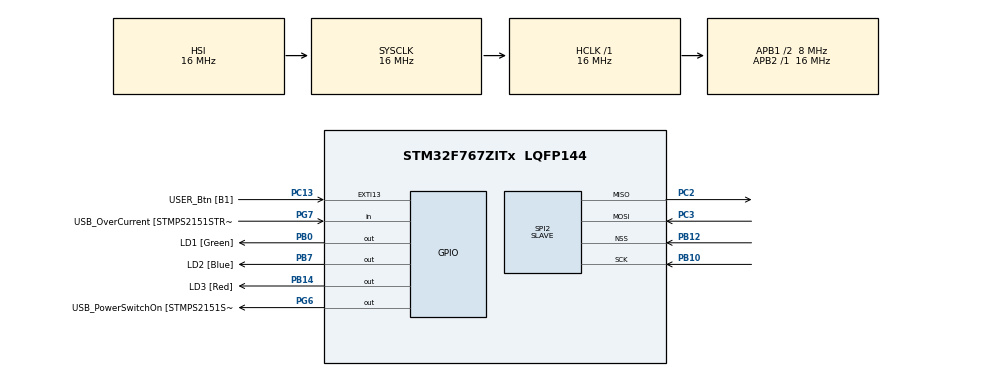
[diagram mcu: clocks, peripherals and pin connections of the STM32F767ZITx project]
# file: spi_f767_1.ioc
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Dma.Request0=SPI2_RX
Dma.Request1=SPI2_TX
Dma.SPI2_RX.0.Direction=DMA_PERIPH_TO_MEMORY
Dma.SPI2_RX.0.FIFOMode=DMA_FIFOMODE_DISABLE
Dma.SPI2_RX.0.Instance=DMA1_Stream1
Dma.SPI2_RX.0.MemDataAlignment=DMA_MDATAALIGN_BYTE
Dma.SPI2_RX.0.MemInc=DMA_MINC_ENABLE
Dma.SPI2_RX.0.Mode=DMA_NORMAL
Dma.SPI2_RX.0.PeriphDataAlignment=DMA_PDATAALIGN_BYTE
Dma.SPI2_RX.0.PeriphInc=DMA_PINC_DISABLE
Dma.SPI2_RX.0.Priority=DMA_PRIORITY_LOW
Dma.SPI2_TX.1.Direction=DMA_MEMORY_TO_PERIPH
Dma.SPI2_TX.1.FIFOMode=DMA_FIFOMODE_DISABLE
Dma.SPI2_TX.1.Instance=DMA1_Stream4
Dma.SPI2_TX.1.MemDataAlignment=DMA_MDATAALIGN_BYTE
Dma.SPI2_TX.1.MemInc=DMA_MINC_ENABLE
Dma.SPI2_TX.1.Mode=DMA_NORMAL
Dma.SPI2_TX.1.PeriphDataAlignment=DMA_PDATAALIGN_BYTE
Dma.SPI2_TX.1.PeriphInc=DMA_PINC_DISABLE
Dma.SPI2_TX.1.Priority=DMA_PRIORITY_LOW
FREERTOS.BinarySemaphores01=spi_data,Dynamic,NULL
FREERTOS.Tasks01=defaultTask,24,128,StartDefaultTask,Default,NULL,Dynamic,NULL,NULL;spi_handler,25,128,spi_handler_entry,Default,NULL,Dynamic,NULL,NULL
FREERTOS.configUSE_NEWLIB_REENTRANT=1
Mcu.Family=STM32F7
Mcu.Name=STM32F767ZITx
Mcu.Package=LQFP144
NVIC.DMA1_Stream1_IRQn=true\:5\:0\:false\:false\:true\:true\:false\:true\:true
NVIC.DMA1_Stream4_IRQn=true\:5\:0\:false\:false\:true\:true\:false\:true\:true
NVIC.PriorityGroup=NVIC_PRIORITYGROUP_4
NVIC.SPI2_IRQn=true\:5\:0\:false\:false\:true\:true\:true\:true\:true
PA1.GPIO_Label=RMII_REF_CLK [LAN8742A-CZ-TR_REFCLK0]
PA1.Signal=ETH_REF_CLK
PA10.GPIO_Label=USB_ID
PA10.Signal=USB_OTG_FS_ID
PA11.GPIO_Label=USB_DM
PA11.Signal=USB_OTG_FS_DM
PA12.GPIO_Label=USB_DP
PA12.Signal=USB_OTG_FS_DP
PA13.GPIO_Label=TMS
PA13.Signal=SYS_JTMS-SWDIO
PA14.GPIO_Label=TCK
PA14.Signal=SYS_JTCK-SWCLK
PA2.GPIO_Label=RMII_MDIO [LAN8742A-CZ-TR_MDIO]
PA2.Signal=ETH_MDIO
PA7.GPIO_Label=RMII_CRS_DV [LAN8742A-CZ-TR_CRS_DV]
PA7.Signal=ETH_CRS_DV
PA8.GPIO_Label=USB_SOF [TP1]
PA8.Signal=USB_OTG_FS_SOF
PA9.GPIO_Label=USB_VBUS
PA9.Signal=USB_OTG_FS_VBUS
PB0.GPIO_Label=LD1 [Green]
PB0.Signal=GPIO_Output
PB10.Mode=Full_Duplex_Slave
PB10.Signal=SPI2_SCK
PB12.Mode=NSS_Signal_Hard_Input
PB12.Signal=SPI2_NSS
PB13.GPIO_Label=RMII_TXD1 [LAN8742A-CZ-TR_TXD1]
PB13.Signal=ETH_TXD1
PB14.GPIO_Label=LD3 [Red]
PB14.Signal=GPIO_Output
PB3.GPIO_Label=SW0
PB3.Signal=SYS_JTDO-SWO
PB7.GPIO_Label=LD2 [Blue]
PB7.Signal=GPIO_Output
PC1.GPIO_Label=RMII_MDC [LAN8742A-CZ-TR_MDC]
PC1.Signal=ETH_MDC
PC13.GPIO_Label=USER_Btn [B1]
PC13.Signal=GPXTI13
PC14/OSC32_IN.Signal=RCC_OSC32_IN
PC15/OSC32_OUT.Signal=RCC_OSC32_OUT
PC2.Mode=Full_Duplex_Slave
PC2.Signal=SPI2_MISO
PC3.Mode=Full_Duplex_Slave
PC3.Signal=SPI2_MOSI
PC4.GPIO_Label=RMII_RXD0 [LAN8742A-CZ-TR_RXD0]
PC4.Signal=ETH_RXD0
PC5.GPIO_Label=RMII_RXD1 [LAN8742A-CZ-TR_RXD1]
PC5.Signal=ETH_RXD1
PD8.GPIO_Label=STLK_RX [STM32F103CBT6_PA3]
PD8.Signal=USART3_TX
PD9.GPIO_Label=STLK_TX [STM32F103CBT6_PA2]
PD9.Signal=USART3_RX
PG11.GPIO_Label=RMII_TX_EN [LAN8742A-CZ-TR_TXEN]
PG11.Signal=ETH_TX_EN
PG13.GPIO_Label=RMII_TXD0 [LAN8742A-CZ-TR_TXD0]
PG13.Signal=ETH_TXD0
PG6.GPIO_Label=USB_PowerSwitchOn [STMPS2151STR_EN]
PG6.Signal=GPIO_Output
PG7.GPIO_Label=USB_OverCurrent [STMPS2151STR_FAULT]
PG7.Signal=GPIO_Input
PH0/OSC_IN.GPIO_Label=MCO [STM32F103CBT6_PA8]
PH0/OSC_IN.Signal=RCC_OSC_IN
PH1/OSC_OUT.Signal=RCC_OSC_OUT
ProjectManager.HeapSize=0x200
ProjectManager.StackSize=0x400
ProjectManager.TargetToolchain=STM32CubeIDE
RCC.48MHZClocksFreq_Value=24000000
RCC.AHBFreq_Value=16000000
RCC.APB1CLKDivider=RCC_HCLK_DIV2
RCC.APB1Freq_Value=8000000
RCC.APB1TimFreq_Value=16000000
RCC.APB2Freq_Value=16000000
RCC.APB2TimFreq_Value=16000000
RCC.CortexFreq_Value=16000000
RCC.HCLKFreq_Value=16000000
RCC.HSE_VALUE=16000000
RCC.HSI_VALUE=16000000
RCC.LSE_VALUE=32768
RCC.PLLMUL=RCC_PLL_MUL9
RCC.PRESCALERUSB=RCC_USBCLKSOURCE_PLL_DIV1_5
RCC.SYSCLKFreq_VALUE=16000000
RCC.SYSCLKSourceVirtual=RCC_SYSCLKSOURCE_PLLCLK
RCC.USBFreq_Value=96000000
RCC.VCOOutputFreq_Value=192000000
SPI2.DataSize=SPI_DATASIZE_8BIT
SPI2.Direction=SPI_DIRECTION_2LINES
SPI2.Mode=SPI_MODE_SLAVE
SPI2.VirtualNSS=VM_NSSHARD
SPI2.VirtualType=VM_SLAVE
VP_FREERTOS_VS_CMSIS_V2.Mode=CMSIS_V2
board=NUCLEO-F767ZI

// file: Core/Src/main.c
/* USER CODE BEGIN Header */
/**
  ******************************************************************************
  * @file           : main.c
  * @brief          : Main program body
  ******************************************************************************
  * @attention
  *
  * Copyright (c) 2024 STMicroelectronics.
  * All rights reserved.
  *
  * This software is licensed under terms that can be found in the LICENSE file
  * in the root directory of this software component.
  * If no LICENSE file comes with this software, it is provided AS-IS.
  *
  ******************************************************************************
  */
/* USER CODE END Header */
#include "main.h"
#include "cmsis_os.h"

SPI_HandleTypeDef hspi2;
DMA_HandleTypeDef hdma_spi2_rx;
DMA_HandleTypeDef hdma_spi2_tx;

/* Definitions for defaultTask */
osThreadId_t defaultTaskHandle;
const osThreadAttr_t defaultTask_attributes = {
  .name = "defaultTask",
  .stack_size = 128 * 4,
  .priority = (osPriority_t) osPriorityNormal,
};
/* Definitions for spi_handler */
osThreadId_t spi_handlerHandle;
const osThreadAttr_t spi_handler_attributes = {
  .name = "spi_handler",
  .stack_size = 128 * 4,
  .priority = (osPriority_t) osPriorityNormal1,
};
/* Definitions for spi_data */
osSemaphoreId_t spi_dataHandle;
const osSemaphoreAttr_t spi_data_attributes = {
  .name = "spi_data"
};

void SystemClock_Config(void);
static void MX_GPIO_Init(void);
static void MX_DMA_Init(void);
static void MX_SPI2_Init(void);
void StartDefaultTask(void *argument);
void spi_handler_entry(void *argument);

/* USER CODE BEGIN 0 */
#define TRANSFER_SIZE 64

uint8_t transfer_bytes[TRANSFER_SIZE] = {0};

void HAL_SPI_RxCpltCallback(SPI_HandleTypeDef *hspi)
{
	//HAL_SPI_Receive_IT(&hspi2, transfer_bytes, TRANSFER_SIZE);
	HAL_GPIO_TogglePin(GPIOB, GPIO_PIN_14);
	osSemaphoreRelease(spi_dataHandle);

}
void HAL_SPI_TxCpltCallback(SPI_HandleTypeDef *hspi)
{
	HAL_SPI_Receive_DMA(&hspi2, transfer_bytes, TRANSFER_SIZE);

}
/* USER CODE END 0 */

int main(void)
{

  /* MCU Configuration--------------------------------------------------------*/

  /* Reset of all peripherals, Initializes the Flash interface and the Systick. */
  HAL_Init();

  /* Configure the system clock */
  SystemClock_Config();

  /* Initialize all configured peripherals */
  MX_GPIO_Init();
  MX_DMA_Init();
  MX_SPI2_Init();
  /* USER CODE BEGIN 2 */
  HAL_SPI_Receive_DMA(&hspi2, transfer_bytes, TRANSFER_SIZE);

  /* USER CODE END 2 */

  /* Init scheduler */
  osKernelInitialize();

  /* Create the semaphores(s) */
  /* creation of spi_data */
  spi_dataHandle = osSemaphoreNew(1, 0, &spi_data_attributes);

  /* Create the thread(s) */
  /* creation of defaultTask */
  defaultTaskHandle = osThreadNew(StartDefaultTask, NULL, &defaultTask_attributes);

  /* creation of spi_handler */
  spi_handlerHandle = osThreadNew(spi_handler_entry, NULL, &spi_handler_attributes);

  /* Start scheduler */
  osKernelStart();

  /* We should never get here as control is now taken by the scheduler */

  /* Infinite loop */
  while (1)
  {

  }
}

void SystemClock_Config(void)
{
  RCC_OscInitTypeDef RCC_OscInitStruct = {0};
  RCC_ClkInitTypeDef RCC_ClkInitStruct = {0};

  /** Configure the main internal regulator output voltage
  */
  __HAL_RCC_PWR_CLK_ENABLE();
  __HAL_PWR_VOLTAGESCALING_CONFIG(PWR_REGULATOR_VOLTAGE_SCALE3);

  /** Initializes the RCC Oscillators according to the specified parameters
  * in the RCC_OscInitTypeDef structure.
  */
  RCC_OscInitStruct.OscillatorType = RCC_OSCILLATORTYPE_HSI;
  RCC_OscInitStruct.HSIState = RCC_HSI_ON;
  RCC_OscInitStruct.HSICalibrationValue = RCC_HSICALIBRATION_DEFAULT;
  RCC_OscInitStruct.PLL.PLLState = RCC_PLL_NONE;
  if (HAL_RCC_OscConfig(&RCC_OscInitStruct) != HAL_OK)
  {
    Error_Handler();
  }

  /** Initializes the CPU, AHB and APB buses clocks
  */
  RCC_ClkInitStruct.ClockType = RCC_CLOCKTYPE_HCLK|RCC_CLOCKTYPE_SYSCLK
                              |RCC_CLOCKTYPE_PCLK1|RCC_CLOCKTYPE_PCLK2;
  RCC_ClkInitStruct.SYSCLKSource = RCC_SYSCLKSOURCE_HSI;
  RCC_ClkInitStruct.AHBCLKDivider = RCC_SYSCLK_DIV1;
  RCC_ClkInitStruct.APB1CLKDivider = RCC_HCLK_DIV2;
  RCC_ClkInitStruct.APB2CLKDivider = RCC_HCLK_DIV1;

  if (HAL_RCC_ClockConfig(&RCC_ClkInitStruct, FLASH_LATENCY_0) != HAL_OK)
  {
    Error_Handler();
  }
}

static void MX_SPI2_Init(void)
{

  /* SPI2 parameter configuration*/
  hspi2.Instance = SPI2;
  hspi2.Init.Mode = SPI_MODE_SLAVE;
  hspi2.Init.Direction = SPI_DIRECTION_2LINES;
  hspi2.Init.DataSize = SPI_DATASIZE_8BIT;
  hspi2.Init.CLKPolarity = SPI_POLARITY_LOW;
  hspi2.Init.CLKPhase = SPI_PHASE_1EDGE;
  hspi2.Init.NSS = SPI_NSS_HARD_INPUT;
  hspi2.Init.FirstBit = SPI_FIRSTBIT_MSB;
  hspi2.Init.TIMode = SPI_TIMODE_DISABLE;
  hspi2.Init.CRCCalculation = SPI_CRCCALCULATION_DISABLE;
  hspi2.Init.CRCPolynomial = 7;
  hspi2.Init.CRCLength = SPI_CRC_LENGTH_DATASIZE;
  hspi2.Init.NSSPMode = SPI_NSS_PULSE_DISABLE;
  if (HAL_SPI_Init(&hspi2) != HAL_OK)
  {
    Error_Handler();
  }

}

static void MX_DMA_Init(void)
{

  /* DMA controller clock enable */
  __HAL_RCC_DMA1_CLK_ENABLE();

  /* DMA interrupt init */
  /* DMA1_Stream1_IRQn interrupt configuration */
  HAL_NVIC_SetPriority(DMA1_Stream1_IRQn, 5, 0);
  HAL_NVIC_EnableIRQ(DMA1_Stream1_IRQn);
  /* DMA1_Stream4_IRQn interrupt configuration */
  HAL_NVIC_SetPriority(DMA1_Stream4_IRQn, 5, 0);
  HAL_NVIC_EnableIRQ(DMA1_Stream4_IRQn);

}

static void MX_GPIO_Init(void)
{
  GPIO_InitTypeDef GPIO_InitStruct = {0};

  /* GPIO Ports Clock Enable */
  __HAL_RCC_GPIOC_CLK_ENABLE();
  __HAL_RCC_GPIOH_CLK_ENABLE();
  __HAL_RCC_GPIOA_CLK_ENABLE();
  __HAL_RCC_GPIOB_CLK_ENABLE();
  __HAL_RCC_GPIOD_CLK_ENABLE();
  __HAL_RCC_GPIOG_CLK_ENABLE();

  /*Configure GPIO pin Output Level */
  HAL_GPIO_WritePin(GPIOB, LD1_Pin|LD3_Pin|LD2_Pin, GPIO_PIN_RESET);

  /*Configure GPIO pin Output Level */
  HAL_GPIO_WritePin(USB_PowerSwitchOn_GPIO_Port, USB_PowerSwitchOn_Pin, GPIO_PIN_RESET);

  /*Configure GPIO pin : USER_Btn_Pin */
  GPIO_InitStruct.Pin = USER_Btn_Pin;
  GPIO_InitStruct.Mode = GPIO_MODE_IT_RISING;
  GPIO_InitStruct.Pull = GPIO_NOPULL;
  HAL_GPIO_Init(USER_Btn_GPIO_Port, &GPIO_InitStruct);

  /*Configure GPIO pins : RMII_MDC_Pin RMII_RXD0_Pin RMII_RXD1_Pin */
  GPIO_InitStruct.Pin = RMII_MDC_Pin|RMII_RXD0_Pin|RMII_RXD1_Pin;
  GPIO_InitStruct.Mode = GPIO_MODE_AF_PP;
  GPIO_InitStruct.Pull = GPIO_NOPULL;
  GPIO_InitStruct.Speed = GPIO_SPEED_FREQ_VERY_HIGH;
  GPIO_InitStruct.Alternate = GPIO_AF11_ETH;
  HAL_GPIO_Init(GPIOC, &GPIO_InitStruct);

  /*Configure GPIO pins : RMII_REF_CLK_Pin RMII_MDIO_Pin RMII_CRS_DV_Pin */
  GPIO_InitStruct.Pin = RMII_REF_CLK_Pin|RMII_MDIO_Pin|RMII_CRS_DV_Pin;
  GPIO_InitStruct.Mode = GPIO_MODE_AF_PP;
  GPIO_InitStruct.Pull = GPIO_NOPULL;
  GPIO_InitStruct.Speed = GPIO_SPEED_FREQ_VERY_HIGH;
  GPIO_InitStruct.Alternate = GPIO_AF11_ETH;
  HAL_GPIO_Init(GPIOA, &GPIO_InitStruct);

  /*Configure GPIO pins : LD1_Pin LD3_Pin LD2_Pin */
  GPIO_InitStruct.Pin = LD1_Pin|LD3_Pin|LD2_Pin;
  GPIO_InitStruct.Mode = GPIO_MODE_OUTPUT_PP;
  GPIO_InitStruct.Pull = GPIO_NOPULL;
  GPIO_InitStruct.Speed = GPIO_SPEED_FREQ_LOW;
  HAL_GPIO_Init(GPIOB, &GPIO_InitStruct);

  /*Configure GPIO pin : RMII_TXD1_Pin */
  GPIO_InitStruct.Pin = RMII_TXD1_Pin;
  GPIO_InitStruct.Mode = GPIO_MODE_AF_PP;
  GPIO_InitStruct.Pull = GPIO_NOPULL;
  GPIO_InitStruct.Speed = GPIO_SPEED_FREQ_VERY_HIGH;
  GPIO_InitStruct.Alternate = GPIO_AF11_ETH;
  HAL_GPIO_Init(RMII_TXD1_GPIO_Port, &GPIO_InitStruct);

  /*Configure GPIO pins : STLK_RX_Pin STLK_TX_Pin */
  GPIO_InitStruct.Pin = STLK_RX_Pin|STLK_TX_Pin;
  GPIO_InitStruct.Mode = GPIO_MODE_AF_PP;
  GPIO_InitStruct.Pull = GPIO_NOPULL;
  GPIO_InitStruct.Speed = GPIO_SPEED_FREQ_VERY_HIGH;
  GPIO_InitStruct.Alternate = GPIO_AF7_USART3;
  HAL_GPIO_Init(GPIOD, &GPIO_InitStruct);

  /*Configure GPIO pin : USB_PowerSwitchOn_Pin */
  GPIO_InitStruct.Pin = USB_PowerSwitchOn_Pin;
  GPIO_InitStruct.Mode = GPIO_MODE_OUTPUT_PP;
  GPIO_InitStruct.Pull = GPIO_NOPULL;
  GPIO_InitStruct.Speed = GPIO_SPEED_FREQ_LOW;
  HAL_GPIO_Init(USB_PowerSwitchOn_GPIO_Port, &GPIO_InitStruct);

  /*Configure GPIO pin : USB_OverCurrent_Pin */
  GPIO_InitStruct.Pin = USB_OverCurrent_Pin;
  GPIO_InitStruct.Mode = GPIO_MODE_INPUT;
  GPIO_InitStruct.Pull = GPIO_NOPULL;
  HAL_GPIO_Init(USB_OverCurrent_GPIO_Port, &GPIO_InitStruct);

  /*Configure GPIO pins : USB_SOF_Pin USB_ID_Pin USB_DM_Pin USB_DP_Pin */
  GPIO_InitStruct.Pin = USB_SOF_Pin|USB_ID_Pin|USB_DM_Pin|USB_DP_Pin;
  GPIO_InitStruct.Mode = GPIO_MODE_AF_PP;
  GPIO_InitStruct.Pull = GPIO_NOPULL;
  GPIO_InitStruct.Speed = GPIO_SPEED_FREQ_VERY_HIGH;
  GPIO_InitStruct.Alternate = GPIO_AF10_OTG_FS;
  HAL_GPIO_Init(GPIOA, &GPIO_InitStruct);

  /*Configure GPIO pin : USB_VBUS_Pin */
  GPIO_InitStruct.Pin = USB_VBUS_Pin;
  GPIO_InitStruct.Mode = GPIO_MODE_INPUT;
  GPIO_InitStruct.Pull = GPIO_NOPULL;
  HAL_GPIO_Init(USB_VBUS_GPIO_Port, &GPIO_InitStruct);

  /*Configure GPIO pins : RMII_TX_EN_Pin RMII_TXD0_Pin */
  GPIO_InitStruct.Pin = RMII_TX_EN_Pin|RMII_TXD0_Pin;
  GPIO_InitStruct.Mode = GPIO_MODE_AF_PP;
  GPIO_InitStruct.Pull = GPIO_NOPULL;
  GPIO_InitStruct.Speed = GPIO_SPEED_FREQ_VERY_HIGH;
  GPIO_InitStruct.Alternate = GPIO_AF11_ETH;
  HAL_GPIO_Init(GPIOG, &GPIO_InitStruct);

}

void StartDefaultTask(void *argument)
{
  for(;;)
  {
    osDelay(1);
  }
}

void spi_handler_entry(void *argument)
{
  /* USER CODE BEGIN spi_handler_entry */
  /* Infinite loop */
  for(;;)
  {

	osSemaphoreAcquire(spi_dataHandle, portMAX_DELAY);

	for(uint8_t i = 0; i < TRANSFER_SIZE; i++){
	  transfer_bytes[i] += 1;
	}

	HAL_SPI_Transmit_DMA(&hspi2, transfer_bytes, TRANSFER_SIZE);

  }
  /* USER CODE END spi_handler_entry */
}

void Error_Handler(void)
{
  __disable_irq();
  while (1)
  {
  }
}
